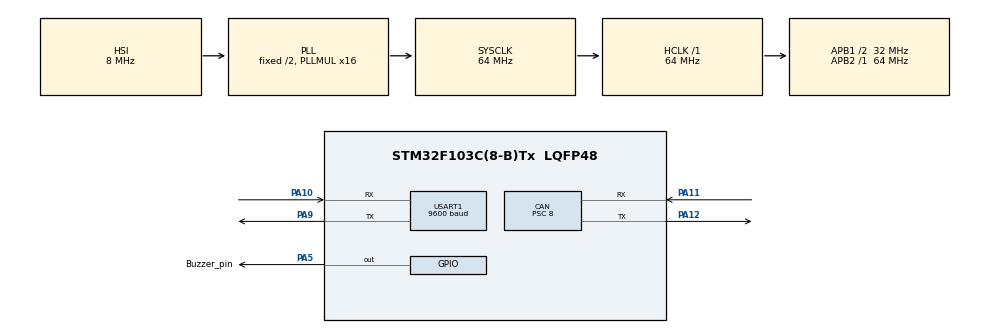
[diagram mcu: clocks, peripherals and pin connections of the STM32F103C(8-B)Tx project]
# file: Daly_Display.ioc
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CAN.BS1=CAN_BS1_13TQ
CAN.BS2=CAN_BS2_2TQ
CAN.CalculateBaudRate=250000
CAN.CalculateTimeBit=4000
CAN.CalculateTimeQuantum=250.0
CAN.Mode=CAN_MODE_NORMAL
CAN.Prescaler=8
CAN.SJW=CAN_SJW_1TQ
IWDG.Prescaler=IWDG_PRESCALER_32
IWDG.Reload=4000
Mcu.Family=STM32F1
Mcu.Name=STM32F103C(8-B)Tx
Mcu.Package=LQFP48
NVIC.CAN1_RX1_IRQn=true\:0\:0\:false\:false\:true\:true\:true\:true
NVIC.CAN1_SCE_IRQn=true\:0\:0\:false\:false\:true\:true\:true\:true
NVIC.PriorityGroup=NVIC_PRIORITYGROUP_4
NVIC.TIM1_UP_IRQn=true\:0\:0\:false\:false\:true\:true\:true\:true
NVIC.TIM2_IRQn=true\:0\:0\:false\:false\:true\:true\:true\:true
NVIC.TIM3_IRQn=true\:0\:0\:false\:false\:true\:true\:true\:true
NVIC.USART1_IRQn=true\:0\:0\:false\:false\:true\:true\:true\:true
NVIC.USB_HP_CAN1_TX_IRQn=true\:0\:0\:false\:false\:true\:true\:true\:true
NVIC.USB_LP_CAN1_RX0_IRQn=true\:0\:0\:false\:false\:true\:true\:true\:true
PA10.Mode=Asynchronous
PA10.Signal=USART1_RX
PA11.Mode=CAN_Activate
PA11.Signal=CAN_RX
PA12.Mode=CAN_Activate
PA12.Signal=CAN_TX
PA13.Mode=Serial_Wire
PA13.Signal=SYS_JTMS-SWDIO
PA14.Mode=Serial_Wire
PA14.Signal=SYS_JTCK-SWCLK
PA5.GPIO_Label=Buzzer_pin
PA5.Signal=GPIO_Output
PA9.Mode=Asynchronous
PA9.Signal=USART1_TX
PC14-OSC32_IN.Mode=LSE-External-Oscillator
PC14-OSC32_IN.Signal=RCC_OSC32_IN
PC15-OSC32_OUT.Mode=LSE-External-Oscillator
PC15-OSC32_OUT.Signal=RCC_OSC32_OUT
PD0-OSC_IN.Mode=HSE-External-Oscillator
PD0-OSC_IN.Signal=RCC_OSC_IN
PD1-OSC_OUT.Mode=HSE-External-Oscillator
PD1-OSC_OUT.Signal=RCC_OSC_OUT
ProjectManager.HeapSize=0x200
ProjectManager.StackSize=0x400
ProjectManager.TargetToolchain=STM32CubeIDE
RCC.AHBFreq_Value=64000000
RCC.APB1CLKDivider=RCC_HCLK_DIV2
RCC.APB1Freq_Value=32000000
RCC.APB1TimFreq_Value=64000000
RCC.APB2Freq_Value=64000000
RCC.APB2TimFreq_Value=64000000
RCC.HCLKFreq_Value=64000000
RCC.PLLMUL=RCC_PLL_MUL16
RCC.SYSCLKFreq_VALUE=64000000
RCC.SYSCLKSource=RCC_SYSCLKSOURCE_PLLCLK
RCC.USBFreq_Value=64000000
TIM1.Period=5000
TIM1.Prescaler=6400
TIM2.Period=5000
TIM2.Prescaler=64000
TIM3.Period=2000
TIM3.Prescaler=64000
USART1.BaudRate=9600
USART1.VirtualMode=VM_ASYNC
USART1.WordLength=WORDLENGTH_8B
VP_IWDG_VS_IWDG.Mode=IWDG_Activate
VP_TIM1_VS_ClockSourceINT.Mode=Internal
VP_TIM2_VS_ClockSourceINT.Mode=Internal
VP_TIM3_VS_ClockSourceINT.Mode=Internal
board=custom

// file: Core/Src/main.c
/* USER CODE BEGIN Header */
/**
  ******************************************************************************
  * @file           : main.c
  * @brief          : Main program body
  ******************************************************************************
  * @attention
  *
  * Copyright (c) 2024 STMicroelectronics.
  * All rights reserved.
  *
  * This software is licensed under terms that can be found in the LICENSE file
  * in the root directory of this software component.
  * If no LICENSE file comes with this software, it is provided AS-IS.
  *
  ******************************************************************************
  */
/* USER CODE END Header */
#include "main.h"
#include "can.h"
#include "iwdg.h"
#include "tim.h"
#include "usart.h"
#include "gpio.h"

/* USER CODE BEGIN Includes */
#include "app.h"
/* USER CODE END Includes */

void SystemClock_Config(void);

int main(void)
{

  /* MCU Configuration--------------------------------------------------------*/

  /* Reset of all peripherals, Initializes the Flash interface and the Systick. */
  HAL_Init();

  /* Configure the system clock */
  SystemClock_Config();

  /* Initialize all configured peripherals */
  MX_GPIO_Init();
  MX_CAN_Init();
  MX_USART1_UART_Init();
  MX_TIM1_Init();
  MX_TIM2_Init();
  MX_IWDG_Init();
  MX_TIM3_Init();
  /* USER CODE BEGIN 2 */

  app_init();
  can_init();
  timer_init();
  app_handler();

  /* USER CODE END 2 */

  /* Infinite loop */
  while (1)
  {

  }
}

void SystemClock_Config(void)
{
  RCC_OscInitTypeDef RCC_OscInitStruct = {0};
  RCC_ClkInitTypeDef RCC_ClkInitStruct = {0};

  /** Initializes the RCC Oscillators according to the specified parameters
  * in the RCC_OscInitTypeDef structure.
  */
  RCC_OscInitStruct.OscillatorType = RCC_OSCILLATORTYPE_HSI|RCC_OSCILLATORTYPE_LSI;
  RCC_OscInitStruct.HSIState = RCC_HSI_ON;
  RCC_OscInitStruct.HSICalibrationValue = RCC_HSICALIBRATION_DEFAULT;
  RCC_OscInitStruct.LSIState = RCC_LSI_ON;
  RCC_OscInitStruct.PLL.PLLState = RCC_PLL_ON;
  RCC_OscInitStruct.PLL.PLLSource = RCC_PLLSOURCE_HSI_DIV2;
  RCC_OscInitStruct.PLL.PLLMUL = RCC_PLL_MUL16;
  if (HAL_RCC_OscConfig(&RCC_OscInitStruct) != HAL_OK)
  {
    Error_Handler();
  }

  /** Initializes the CPU, AHB and APB buses clocks
  */
  RCC_ClkInitStruct.ClockType = RCC_CLOCKTYPE_HCLK|RCC_CLOCKTYPE_SYSCLK
                              |RCC_CLOCKTYPE_PCLK1|RCC_CLOCKTYPE_PCLK2;
  RCC_ClkInitStruct.SYSCLKSource = RCC_SYSCLKSOURCE_PLLCLK;
  RCC_ClkInitStruct.AHBCLKDivider = RCC_SYSCLK_DIV1;
  RCC_ClkInitStruct.APB1CLKDivider = RCC_HCLK_DIV2;
  RCC_ClkInitStruct.APB2CLKDivider = RCC_HCLK_DIV1;

  if (HAL_RCC_ClockConfig(&RCC_ClkInitStruct, FLASH_LATENCY_2) != HAL_OK)
  {
    Error_Handler();
  }
}

void Error_Handler(void)
{
  __disable_irq();
  while (1)
  {
  }
}
